# LPC43xx register map
File version: 10
Register cmsis file for LPC43xx parts
CPU: CM4 r0p0, little endian, no MPU, no FPU, 3 interrupt priority bits
Registers are 32-bit, read-write, reset 0x0 unless marked. A register's access mark holds for its fields unless they carry their own. Offsets are from the block's base; lines under a group give offsets from that group; [hi:lo] are bit positions; {n}, {i} and the like mark numbered series; 'fields as' and 'values as' point back to an identical list; <NAME> marks a mode.

## Memory map
0x40000000 SCT size 0x1000 — State Configurable Timer (SCT) with dither engine
0x40002000 GPDMA size 0x1000 — General Purpose DMA (GPDMA)
0x40003000 SPIFI size 0x1000 — SPI Flash Interface (SPIFI)
0x40004000 SDMMC size 0x1000
0x40005000 EMC size 0x1000 — External Memory Controller (EMC)
0x40006000 USB0 size 0x1000 — USB0 Host/Device/OTG controller
0x40007000 USB1 size 0x1000 — USB1 Host/Device controller
0x40008000 LCD size 0x1000 — LCD controller
0x4000E000 EEPROM size 0x1000
0x40010000 ETHERNET size 0x2000
0x40040000 ATIMER size 0x1000 — Alarm timer
0x40041000 REGFILE size 0x1000 — RTC REGFILE
0x40042000 PMC size 0x1000 — Power Management Controller (PMC)
0x40043000 CREG size 0x1000 — Configuration Registers (CREG)
0x40044000 EVENTROUTER size 0x1000
0x40046000 RTC size 0x1000 — Real-Time Clock (RTC) and event recorder
0x40050000 CGU size 0x1000 — Clock Generation Unit (CGU)
0x40051000 CCU1 size 0x1000 — Clock Control Unit (CCU)
0x40052000 CCU2 size 0x1000 — Clock Control Unit (CCU2)
0x40053000 RGU size 0x1000 — Reset Generation Unit (RGU)
0x40080000 WWDT size 0x300 — Windowed Watchdog timer (WWDT)
0x40081000 USART0 size 0x300 — USART0_2_3
0x40082000 UART1 size 0x300
0x40083000 SSP0 size 0x300 — SSP0/1
0x40084000 TIMER0 size 0x300 — Timer0/1/2/3
0x40085000 TIMER1 size 0x300
0x40086000 SCU size 0x1000 — System Control Unit (SCU) I/O configuration
0x40087000 GPIO_PIN_INT size 0x1000 — GPIO pin interrupt
0x40088000 GPIO_GROUP_INT0 size 0x1000 — GPIO group interrupt 0
0x40089000 GPIO_GROUP_INT1 size 0x1000
0x400A0000 MCPWM size 0x1000 — Motor Control PWM (MOTOCONPWM)
0x400A1000 I2C0 size 0x1000 — I2C-bus interface
0x400A2000 I2S0 size 0x1000 — I2S interface
0x400A3000 I2S1 size 0x1000
0x400A4000 C_CAN1 size 0x1000 — C_CAN
0x400C0000 RITIMER size 0x1000 — Repetitive Interrupt Timer (RIT)
0x400C1000 USART2 size 0x300
0x400C2000 USART3 size 0x300
0x400C3000 TIMER2 size 0x300
0x400C4000 TIMER3 size 0x300
0x400C5000 SSP1 size 0x300
0x400C6000 QEI size 0x1000 — Quadrature Encoder Interface (QEI)
0x400C7000 GIMA size 0x1000 — Global Input Multiplexer Array (GIMA)
0x400E0000 I2C1 size 0x1000
0x400E1000 DAC size 0x1000 — Digital-to-Analog Converter (DAC)
0x400E2000 C_CAN0 size 0x1000
0x400E3000 ADC0 size 0x1000 — 10-bit Analog-to-Digital Converter (ADC)
0x400E4000 ADC1 size 0x1000
0x400F0000 ADCHS size 0x1000 — 12-bit Analog-to-Digital Converter High-Speed (ADCHS)
0x400F4000 GPIO_PORT size 0x4000
0x40100000 SPI size 0x1000
0x40101000 SGPIO size 0x1000 — Serial GPIO (SGPIO)

## Interrupts
0 DAC
2 DMA (GPDMA)
4 FLASH (EEPROM)
5 ETHERNET
6 SDIO (SDMMC)
7 LCD
8 USB0
9 USB1
10 SCT
11 RITIMER
12 TIMER0
13 TIMER1
14 TIMER2
15 TIMER3
16 MCPWM
17 ADC0
18 I2C0
19 I2C1
20 SPI_INT (SPI)
21 ADC1
22 SSP0
23 SSP1
24 USART0
25 UART1
26 USART2
27 USART3
28 I2S0
29 I2S1
30 SPIFI
31 SGPIO_IINT (SGPIO)
{n+32} PIN_INT{n} (GPIO_PIN_INT) (n=0..7)
40 GINT0 (GPIO_GROUP_INT0)
41 GINT1 (GPIO_GROUP_INT1)
42 EVENTROUTER
43 C_CAN1
45 ADCHS
46 ATIMER
47 RTC
49 WWDT
51 C_CAN0
52 QEI

## EEPROM
Base 0x4000E000
0x00 CMD — EEPROM command register
  [2:0] CMD — Command. Read data shows the last command executed on the EEPROM. 110 = erase/program page All other values are reserved.
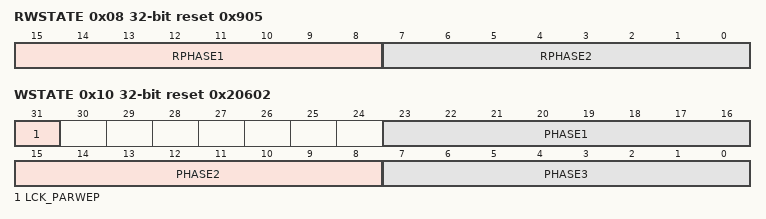
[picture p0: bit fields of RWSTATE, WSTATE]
0x08 RWSTATE reset 0x905 — EEPROM read wait state register
  [15:8] RPHASE1 — Wait states 1 (minus 1 encoded). The number of system clock periods to meet a duration equal to TRPHASE1.
  [7:0] RPHASE2 — Wait states 2 (minus 1 encoded). The number of system clock periods to meet the read operations TRPHASE2 duration.
0x0C AUTOPROG — EEPROM auto programming register
  [1:0] AUTOPROG — Auto programming mode: 00 = auto programming off 01 = erase/program cycle is triggered after 1 word is written 10 = erase/program cycle is triggered after a write to AHB address ending with ......1111100 (last word of a page)
0x10 WSTATE reset 0x20602 — EEPROM wait state register
  [31] LCK_PARWEP — Lock timing parameters for write, erase and program operation 0 = WSTATE and CLKDIV registers have R/W access 1 = WSTATE and CLKDIV registers have R only access
  [23:16] PHASE1 — Wait states for phase 1 (minus 1 encoded). The number of system clock periods to meet a duration equal to TPHASE1.
  [15:8] PHASE2 — Wait states for phase 2 (minus 1 encoded). The number of system clock periods to meet a duration equal to TPHASE2.
  [7:0] PHASE3 — Wait states for phase 3 (minus 1 encoded). The number of system clock periods to meet a duration equal to TPHASE3.
0x14 CLKDIV reset 0x63 — EEPROM clock divider register
  [15:0] CLKDIV — Division factor (minus 1 encoded).
0x18 PWRDWN — EEPROM power-down register
  [0] PWRDWN — Power down mode bit. 0 = not in power down mode. 1 = power down mode.
0xFD8 INTENCLR wo — EEPROM interrupt enable clear
  [2] PROG_CLR_EN — Clear program operation finished interrupt enable bit for EEPROM. 0 = leave corresponding bit unchanged. 1 = clear corresponding bit.
0xFDC INTENSET wo — EEPROM interrupt enable set
  [2] PROG_SET_EN — Set program operation finished interrupt enable bit for EEPROM device 1. 0 = leave corresponding bit unchanged. 1 = set corresponding bit.
0xFE0 INTSTAT ro — EEPROM interrupt status
  [2] END_OF_PROG — EEPROM program operation finished interrupt status bit. Bit is: - set when this operation has finished OR when one is written to the corresponding bit of the INTSTATSET register. - cleared when one is written to the corresponding bit of the INTSTATCLR register.
0xFE4 INTEN ro — EEPROM interrupt enable
  [2] EE_PROG_DONE — EEPROM program operation finished interrupt enable bit. Bit is: - set when one is written in the corresponding bit of the INTENSET register. - cleared when one is written to the corresponding bit of the INTENCLR register.
0xFE8 INTSTATCLR wo — EEPROM interrupt status clear
  [2] PROG_CLR_ST — Clear program operation finished interrupt status bit for EEPROM device. 0 = leave corresponding bit unchanged. 1 = clear corresponding bit.
